VERSION ""

NS_ :

BS_:
BU_: BSI CMB RADIO_CD EMF CLIM
BO_ 535 ETAT_COMBINE: 8 CMB

BO_ 791 inconnu_cmb_1: 8 CMB

BO_ 1311 x_ecu_status: 8 CMB

BO_ 347 EMF_COE_MODIF_PROFILS: 8 EMF

BO_ 359 COMMANDES_EMF: 8 EMF

BO_ 1014 x_config_date: 7 EMF

BO_ 1317 x_ecu_status: 8 EMF

BO_ 1509 x_ecu_infos: 8 EMF

BO_ 272 inconnu_clim_1: 8 CLIM

BO_ 400 inconnu_clim_2: 8 CLIM

BO_ 464 x_commandes_clim: 7 CLIM
   SG_ Temperature_zone_passager : 60|5@0+ (1,0) [0|22] "" Vector__XXX
   SG_ Temperature_zone_conducteur : 52|5@0+ (1,0) [0|22] "" Vector__XXX
   SG_ Degivrage_avant : 44|1@0+ (1,0) [0|0] "" Vector__XXX
   SG_ Recyclage_air : 45|1@0+ (1,0) [0|0] "" Vector__XXX
   SG_ direction : 38|3@0+ (1,0) [0|0] "" Vector__XXX

BO_ 1325 x_ecu_status: 8 CLIM

BO_ 164 inconnu_radio_1: 6 RADIO_CD

BO_ 305 x_commandes_changeur_cd: 5 RADIO_CD

BO_ 357 x_etat_radio: 5 RADIO_CD

BO_ 421 x_etat_volume: 1 RADIO_CD

BO_ 480 x_config_radio: 5 RADIO_CD

BO_ 485 x_config_audio: 7 RADIO_CD

BO_ 549 x_freq_radio: 5 RADIO_CD

BO_ 613 x_station_radio: 4 RADIO_CD

BO_ 677 ETAT_RADIO_CD_CD: 8 RADIO_CD

BO_ 805 ETAT_RADIO_CD_CD: 3 RADIO_CD

BO_ 869 ETAT_RADIO_CD_DSK: 5 RADIO_CD

BO_ 933 ETAT_RADIO_CD_TRK: 6 RADIO_CD

BO_ 997 ETAT_CDT: 6 RADIO_CD

BO_ 1312 x_ecu_status: 8 RADIO_CD

BO_ 267 inconnu_inconnu_1: 6 Vector__XXX

BO_ 299 inconnu_inconnu_2: 1 Vector__XXX

BO_ 308 inconnu_inconnu_3: 8 Vector__XXX

BO_ 332 inconnu_inconnu_4: 5 Vector__XXX

BO_ 543 x_commandes_volant: 3 Vector__XXX

BO_ 599 inconnu_inconnu_5: 6 Vector__XXX

BO_ 1184 inconnu_inconnu_6: 1 Vector__XXX

BO_ 1319 x_ecu_status: 8 Vector__XXX

BO_ 1511 x_ecu_infos: 8 Vector__XXX

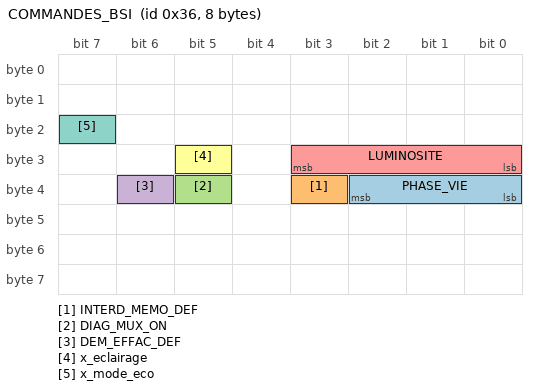
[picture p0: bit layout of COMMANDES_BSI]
BO_ 54 COMMANDES_BSI: 8 BSI
   SG_ PHASE_VIE : 34|3@0+ (1,0) [0|0] "" Vector__XXX
   SG_ INTERD_MEMO_DEF : 35|1@0+ (1,0) [0|0] "" Vector__XXX
   SG_ DIAG_MUX_ON : 37|1@0+ (1,0) [0|0] "" Vector__XXX
   SG_ DEM_EFFAC_DEF : 38|1@0+ (1,0) [0|0] "" Vector__XXX
   SG_ LUMINOSITE : 27|4@0+ (1,0) [0|15] "" Vector__XXX
   SG_ x_eclairage : 29|1@0+ (1,0) [0|0] "" Vector__XXX
   SG_ x_mode_eco : 23|1@0+ (1,0) [0|0] "" Vector__XXX

BO_ 182 DONNEES_BSI_RAPIDES: 8 BSI
   SG_ x_tachymetre : 7|16@0+ (1,0) [0|0] "tr/mn" Vector__XXX
   SG_ x_vitesse : 23|16@0+ (1,0) [0|0] "km/h" Vector__XXX

BO_ 230 x_infos_roues: 6 BSI

BO_ 246 DONNEES_BSI_LENTES: 8 BSI

BO_ 288 x_journal_erreurs: 8 BSI

BO_ 296 CDE_COMBINE_SIGNALISATION: 8 BSI

BO_ 301 x_commandes_clim: 8 BSI

BO_ 353 ETAT_BSI_TEMP_NIVEAU: 7 BSI

BO_ 360 CDE_COMBINE_TEMOINS: 8 BSI

BO_ 417 BSI_CD_PTR_MESSAGE: 8 BSI

BO_ 424 GESTION_VITESSE: 8 BSI

BO_ 544 x_infos_ouvrants: 2 BSI

BO_ 545 INFOS_GEN_ODB: 7 BSI

BO_ 551 inconnu_bsi_1: 6 BSI

BO_ 608 inconnu_bsi_2: 8 BSI

BO_ 609 x_slot1_odb: 7 BSI

BO_ 672 inconnu_bsi_3: 1 BSI

BO_ 673 x_slot2_odb: 7 BSI

BO_ 694 x_vin_fin: 8 BSI

BO_ 737 ETAT_FONCTIONS: 5 BSI

BO_ 822 x_vin_debut: 3 BSI

BO_ 865 inconnu_bsi_4: 6 BSI

BO_ 935 INFOS_MAINTENANCE: 8 BSI

BO_ 950 x_vin_millieu: 7 BSI

BO_ 1042 inconnu_bsi_5: 2 BSI

BO_ 1298 x_ecu_status: 8 BSI

BO_ 1490 x_ecu_infos: 8 BSI

BO_ 1503 x_ecu_infos: 8 CMB

BO_ 1504 x_ecu_infos: 8 RADIO_CD

BO_ 1517 x_ecu_infos: 8 CLIM

BO_ 24 x_status_airbags: 5 Vector__XXX

BA_DEF_ BO_ "GenMsgBackgroundColor" STRING ;
BA_DEF_ BO_ "GenMsgForegroundColor" STRING ;
BA_DEF_DEF_ "GenMsgBackgroundColor" "#ffffff";
BA_DEF_DEF_ "GenMsgForegroundColor" "#000000";
CM_ BU_ BSI "Boitier de Servitude Intelligent";
CM_ BU_ CMB "Combine d'instruments/Cluster";
CM_ BU_ RADIO_CD "Radio CD";
CM_ BU_ EMF "Ecran Multifonctions (type C)";
CM_ BU_ CLIM "Controlleur clim auto";
CM_ BO_ 347 ""codes de modification profil EMF"";
CM_ BO_ 359 "Commandes de l'EMF";
CM_ BO_ 1014 "Configuration de la date";
CM_ BO_ 464 "Commandes du panneau de controle de la clim";
CM_ BO_ 677 "Informations sur le CD insere";
CM_ BO_ 805 "Informations du lecteur CD";
CM_ BO_ 869 "Information sur le CD actuel";
CM_ BO_ 933 "Informations sur la piste CD actuel";
CM_ BO_ 997 "Commandes radio (bouttons de facade)";
CM_ BO_ 267 "Semble lie a 0x12B, Possiblement du boitier toit escamotable";
CM_ BO_ 299 "Semble lie a 0x10B, Possiblement du boitier toit escamotable";
CM_ BO_ 308 "Possiblement du boitier toit escamotable";
CM_ BO_ 332 "Probablement du BSI";
CM_ BO_ 543 "Probablement commandes au volant // Probablement du BSI";
CM_ BO_ 599 "Possiblement du boitier toit escamotable";
CM_ BO_ 1184 "Possiblement du boitier toit escamotable";
CM_ BO_ 1319 "Possiblement du boitier toit escamotable";
CM_ BO_ 1511 "Possiblement du boitier toit escamotable";
CM_ BO_ 54 "Commandes BSI";
CM_ SG_ 54 PHASE_VIE "Gestion_de_l'alimentation";
CM_ SG_ 54 INTERD_MEMO_DEF "Probablement_pour_desactiver_la_memorisation_des_defauts";
CM_ SG_ 54 DIAG_MUX_ON "Probablement_pour_activer_le_diag_on_can";
CM_ SG_ 54 DEM_EFFAC_DEF "Probablement_pour_demander_un_effacement_des_defauts";
CM_ SG_ 54 LUMINOSITE "Luminosite_du_EMF_et_COMBINE";
CM_ SG_ 54 x_eclairage "probablement_activation_du_retroeclairage";
CM_ SG_ 54 x_mode_eco "probablement_mode_eco";
CM_ BO_ 182 "Donnes BSI frequemment mises a jour";
CM_ SG_ 182 x_tachymetre "regime_moteur_x10";
CM_ SG_ 182 x_vitesse "vitesse_x100";
CM_ BO_ 230 "Infos BSI sur les roues et la tension";
CM_ BO_ 353 "(aussi appelle BSI_TEMP)";
CM_ BO_ 24 "Possiblement du BSI, semble donner le status des airbags";
VAL_ 464 Temperature_zone_passager 0 "LO" 0 "15c_-_18c" 0 "18.5c_-_23.5c" 0 "24_-_27" 22 "HI" 0 "";
VAL_ 464 Temperature_zone_conducteur 0 "LO" 0 "15c_-_18c" 0 "18.5c_-_23.5c" 0 "24_-_27" 22 "HI" 0 "";
VAL_ 464 direction 1 "haut_(durant_le_degivrage)" 2 "bas" 3 "millieu" 4 "haut" 5 "millieu_+_bas" 6 "haut_+_bas";
VAL_ 54 PHASE_VIE 0 "VEILLE" 1 "NORMAL" 10 "MISE_EN_VEILLE" 11 "REVEIL" 100 "COM_OFF";
